# ATSAMC21N18A register map
Registers are 32-bit, access not given, no defined reset value unless marked. A register's access mark holds for its fields unless they carry their own. Addresses are absolute; registers are grouped by the start of their names; [hi:lo] are bit positions.

## TC3
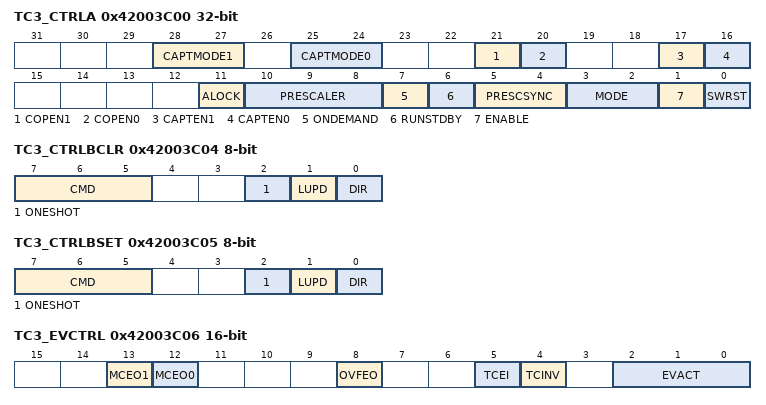
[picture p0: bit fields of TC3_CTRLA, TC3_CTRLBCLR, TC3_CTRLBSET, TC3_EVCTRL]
0x42003C00 TC3_CTRLA — Control A
  [28:27] CAPTMODE1, [25:24] CAPTMODE0, [21] COPEN1, [20] COPEN0, [17] CAPTEN1, [16] CAPTEN0, [11] ALOCK, [10:8] PRESCALER, [7] ONDEMAND, [6] RUNSTDBY, [5:4] PRESCSYNC, [3:2] MODE, [1] ENABLE, [0] SWRST
0x42003C04 TC3_CTRLBCLR 8-bit — Control B Clear
  [7:5] CMD, [2] ONESHOT, [1] LUPD, [0] DIR
0x42003C05 TC3_CTRLBSET 8-bit — Control B Set
  [7:5] CMD, [2] ONESHOT, [1] LUPD, [0] DIR
0x42003C06 TC3_EVCTRL 16-bit — Event Control
  [13] MCEO1, [12] MCEO0, [8] OVFEO, [5] TCEI, [4] TCINV, [2:0] EVACT
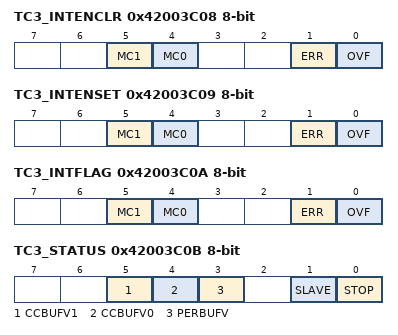
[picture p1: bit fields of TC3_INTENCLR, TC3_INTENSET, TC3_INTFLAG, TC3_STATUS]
0x42003C08 TC3_INTENCLR 8-bit — Interrupt Enable Clear
  [5] MC1, [4] MC0, [1] ERR, [0] OVF
0x42003C09 TC3_INTENSET 8-bit — Interrupt Enable Set
  [5] MC1, [4] MC0, [1] ERR, [0] OVF
0x42003C0A TC3_INTFLAG 8-bit — Interrupt Flag Status and Clear
  [5] MC1, [4] MC0, [1] ERR, [0] OVF
0x42003C0B TC3_STATUS 8-bit — Status
  [5] CCBUFV1, [4] CCBUFV0, [3] PERBUFV, [1] SLAVE, [0] STOP
0x42003C0C TC3_WAVE 8-bit — Waveform Generation Control
  [1:0] WAVEGEN
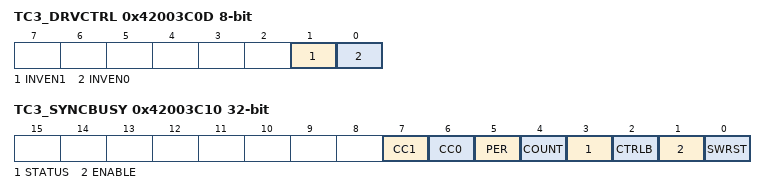
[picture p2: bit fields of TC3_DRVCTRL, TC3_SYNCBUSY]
0x42003C0D TC3_DRVCTRL 8-bit — Control C
  [1] INVEN1, [0] INVEN0
0x42003C0F TC3_DBGCTRL 8-bit — Debug Control
  [0] DBGRUN
0x42003C10 TC3_SYNCBUSY — Synchronization Status
  [7] CC1, [6] CC0, [5] PER, [4] COUNT, [3] STATUS, [2] CTRLB, [1] ENABLE, [0] SWRST
0x42003C14 TC3_COUNT_COUNT8 8-bit — COUNT8 Count
  [7:0] COUNT — Counter Value
0x42003C14 TC3_COUNT_COUNT16 16-bit — COUNT16 Count
  [15:0] COUNT — Counter Value
0x42003C14 TC3_COUNT_COUNT32 — COUNT32 Count
  [31:0] COUNT — Counter Value
0x42003C1B TC3_PER_COUNT8 8-bit — COUNT8 Period
  [7:0] PER — Period Value
0x42003C1C TC3_CC_COUNT8 8-bit — COUNT8 Compare and Capture
  [7:0] CC — Counter/Compare Value
0x42003C1C TC3_CC_COUNT16 16-bit — COUNT16 Compare and Capture
  [15:0] CC — Counter/Compare Value
0x42003C1C TC3_CC_COUNT32 — COUNT32 Compare and Capture
  [31:0] CC — Counter/Compare Value
0x42003C2F TC3_PERBUF_COUNT8 8-bit — COUNT8 Period Buffer
  [7:0] PERBUF — Period Buffer Value
0x42003C30 TC3_CCBUF_COUNT8 8-bit — COUNT8 Compare and Capture Buffer
  [7:0] CCBUF — Counter/Compare Buffer Value
0x42003C30 TC3_CCBUF_COUNT16 16-bit — COUNT16 Compare and Capture Buffer
  [15:0] CCBUF — Counter/Compare Buffer Value
0x42003C30 TC3_CCBUF_COUNT32 — COUNT32 Compare and Capture Buffer
  [31:0] CCBUF — Counter/Compare Buffer Value

## TC4
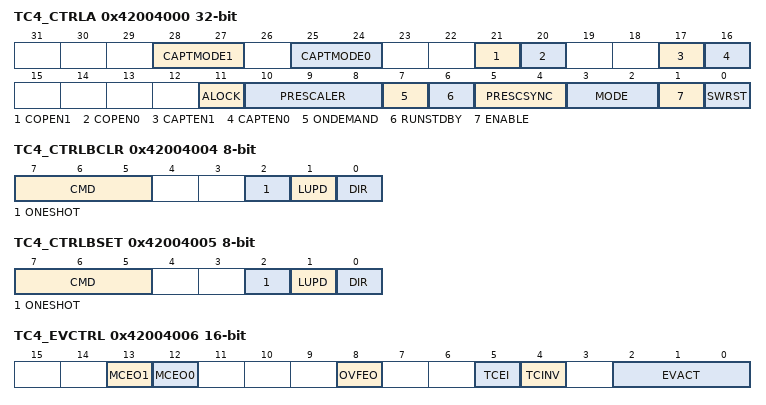
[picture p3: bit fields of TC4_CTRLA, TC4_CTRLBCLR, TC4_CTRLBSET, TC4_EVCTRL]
0x42004000 TC4_CTRLA — Control A
  [28:27] CAPTMODE1, [25:24] CAPTMODE0, [21] COPEN1, [20] COPEN0, [17] CAPTEN1, [16] CAPTEN0, [11] ALOCK, [10:8] PRESCALER, [7] ONDEMAND, [6] RUNSTDBY, [5:4] PRESCSYNC, [3:2] MODE, [1] ENABLE, [0] SWRST
0x42004004 TC4_CTRLBCLR 8-bit — Control B Clear
  [7:5] CMD, [2] ONESHOT, [1] LUPD, [0] DIR
0x42004005 TC4_CTRLBSET 8-bit — Control B Set
  [7:5] CMD, [2] ONESHOT, [1] LUPD, [0] DIR
0x42004006 TC4_EVCTRL 16-bit — Event Control
  [13] MCEO1, [12] MCEO0, [8] OVFEO, [5] TCEI, [4] TCINV, [2:0] EVACT
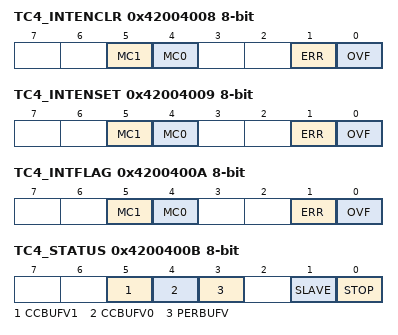
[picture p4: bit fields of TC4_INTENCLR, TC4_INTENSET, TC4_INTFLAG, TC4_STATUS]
0x42004008 TC4_INTENCLR 8-bit — Interrupt Enable Clear
  [5] MC1, [4] MC0, [1] ERR, [0] OVF
0x42004009 TC4_INTENSET 8-bit — Interrupt Enable Set
  [5] MC1, [4] MC0, [1] ERR, [0] OVF
0x4200400A TC4_INTFLAG 8-bit — Interrupt Flag Status and Clear
  [5] MC1, [4] MC0, [1] ERR, [0] OVF
0x4200400B TC4_STATUS 8-bit — Status
  [5] CCBUFV1, [4] CCBUFV0, [3] PERBUFV, [1] SLAVE, [0] STOP
0x4200400C TC4_WAVE 8-bit — Waveform Generation Control
  [1:0] WAVEGEN
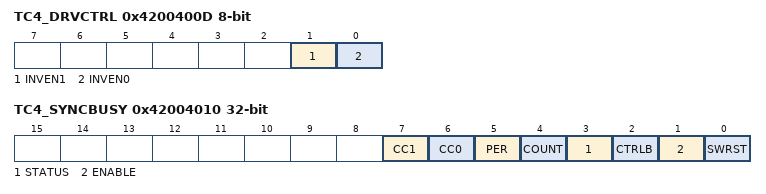
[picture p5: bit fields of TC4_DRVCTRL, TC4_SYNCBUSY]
0x4200400D TC4_DRVCTRL 8-bit — Control C
  [1] INVEN1, [0] INVEN0
0x4200400F TC4_DBGCTRL 8-bit — Debug Control
  [0] DBGRUN
0x42004010 TC4_SYNCBUSY — Synchronization Status
  [7] CC1, [6] CC0, [5] PER, [4] COUNT, [3] STATUS, [2] CTRLB, [1] ENABLE, [0] SWRST
0x42004014 TC4_COUNT_COUNT8 8-bit — COUNT8 Count
  [7:0] COUNT — Counter Value
0x42004014 TC4_COUNT_COUNT16 16-bit — COUNT16 Count
  [15:0] COUNT — Counter Value
0x42004014 TC4_COUNT_COUNT32 — COUNT32 Count
  [31:0] COUNT — Counter Value
0x4200401B TC4_PER_COUNT8 8-bit — COUNT8 Period
  [7:0] PER — Period Value
0x4200401C TC4_CC_COUNT8 8-bit — COUNT8 Compare and Capture
  [7:0] CC — Counter/Compare Value
0x4200401C TC4_CC_COUNT16 16-bit — COUNT16 Compare and Capture
  [15:0] CC — Counter/Compare Value
0x4200401C TC4_CC_COUNT32 — COUNT32 Compare and Capture
  [31:0] CC — Counter/Compare Value
0x4200402F TC4_PERBUF_COUNT8 8-bit — COUNT8 Period Buffer
  [7:0] PERBUF — Period Buffer Value
0x42004030 TC4_CCBUF_COUNT8 8-bit — COUNT8 Compare and Capture Buffer
  [7:0] CCBUF — Counter/Compare Buffer Value
0x42004030 TC4_CCBUF_COUNT16 16-bit — COUNT16 Compare and Capture Buffer
  [15:0] CCBUF — Counter/Compare Buffer Value
0x42004030 TC4_CCBUF_COUNT32 — COUNT32 Compare and Capture Buffer
  [31:0] CCBUF — Counter/Compare Buffer Value
